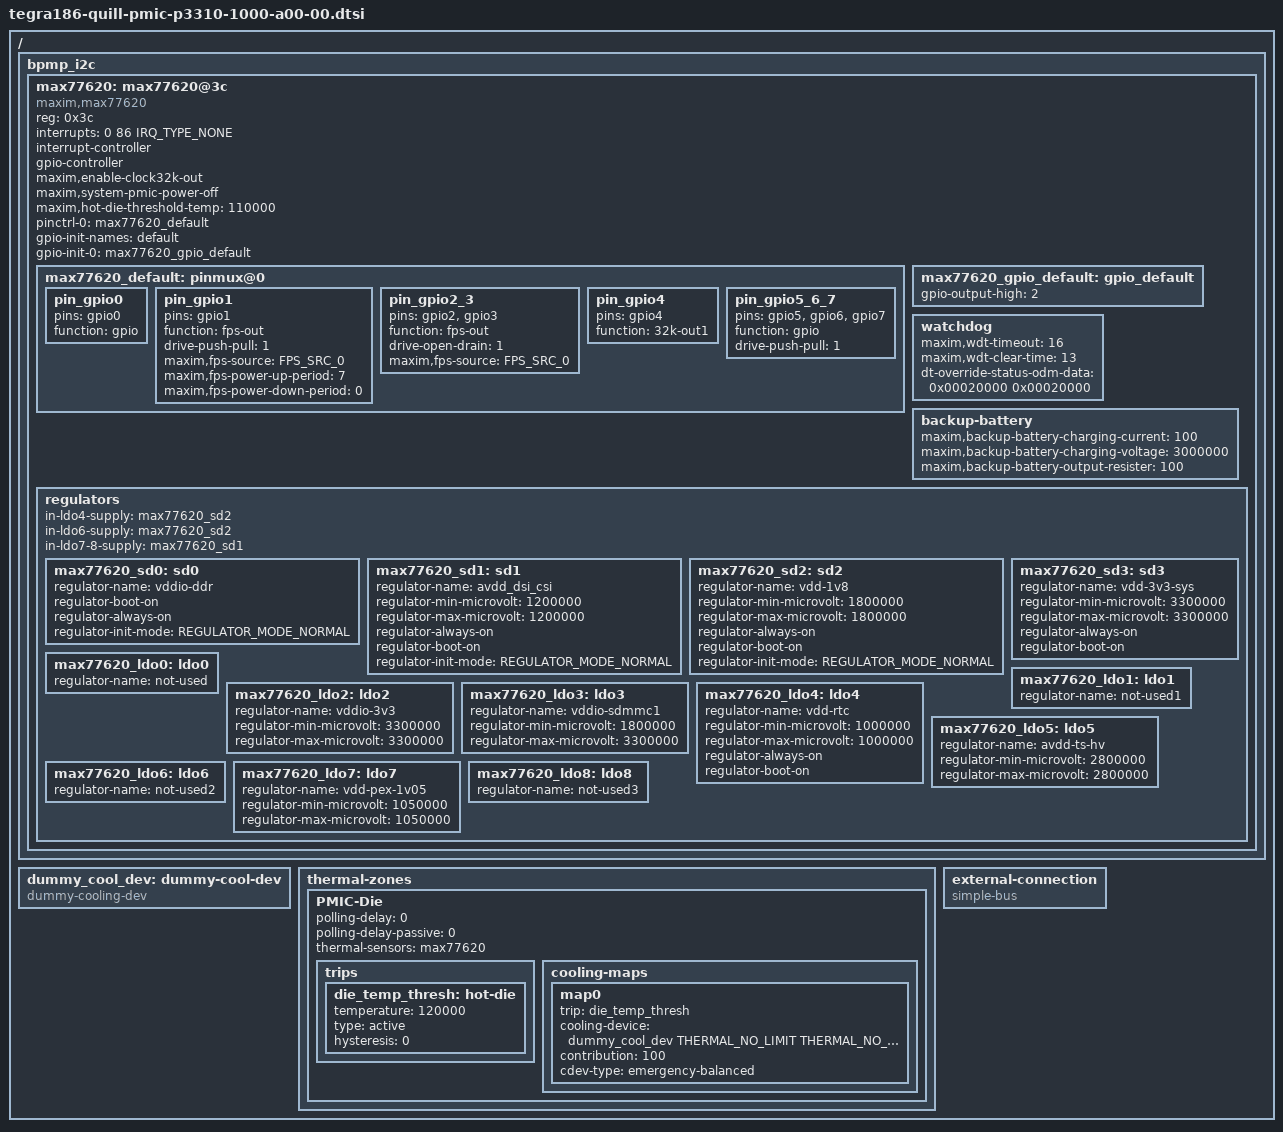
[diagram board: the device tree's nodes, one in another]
/*
 * Copyright (c) 2015, NVIDIA CORPORATION.  All rights reserved.
 *
 * This program is free software; you can redistribute it and/or modify
 * it under the terms of the GNU General Public License as published by
 * the Free Software Foundation; either version 2 of the License, or
 * (at your option) any later version.
 *
 * This program is distributed in the hope that it will be useful, but WITHOUT
 * ANY WARRANTY; without even the implied warranty of MERCHANTABILITY or
 * FITNESS FOR A PARTICULAR PURPOSE.  See the GNU General Public License for
 * more details.
 */

#include <dt-bindings/mfd/max77620.h>
#include <dt-bindings/regulator/regulator.h>
#include <dt-bindings/gpio/tegra-gpio.h>
#include <dt-bindings/thermal/thermal.h>
#include <dt-bindings/interrupt-controller/irq.h>

/ {
	bpmp_i2c {
		max77620: max77620@3c {
			compatible = "maxim,max77620";
			reg = <0x3c>;
			interrupts = <0 86 IRQ_TYPE_NONE>;

			#interrupt-cells = <2>;
                        interrupt-controller;

			gpio-controller;
			#gpio-cells = <2>;

			maxim,enable-clock32k-out;

			maxim,system-pmic-power-off;

			maxim,hot-die-threshold-temp = <110000>;
			#thermal-sensor-cells = <0>;

			pinctrl-names = "default";
			pinctrl-0 = <&max77620_default>;

			gpio-init-names = "default";
			gpio-init-0 = <&max77620_gpio_default>;

			max77620_default: pinmux@0 {
				pin_gpio0 {
					pins = "gpio0";
					function = "gpio";
				};

				pin_gpio1 {
					pins = "gpio1";
					function = "fps-out";
					drive-push-pull = <1>;
					maxim,fps-source = <FPS_SRC_0>;
					maxim,fps-power-up-period = <7>;
					maxim,fps-power-down-period = <0>;
				};

				pin_gpio2_3 {
					pins = "gpio2", "gpio3";
					function = "fps-out";
					drive-open-drain = <1>;
					maxim,fps-source = <FPS_SRC_0>;
				};

				pin_gpio4 {
					pins = "gpio4";
					function = "32k-out1";
				};

				pin_gpio5_6_7 {
					pins = "gpio5", "gpio6", "gpio7";
					function = "gpio";
					drive-push-pull = <1>;
				};
			};

			max77620_gpio_default:gpio_default {
				gpio-output-high = <2>;
			};

			watchdog {
				maxim,wdt-timeout = <16>;
				maxim,wdt-clear-time = <13>;
				status = "okay";
				dt-override-status-odm-data = <0x00020000 0x00020000>;
			};

			backup-battery {
				maxim,backup-battery-charging-current = <100>;
				maxim,backup-battery-charging-voltage = <3000000>;
				maxim,backup-battery-output-resister = <100>;
			};

			regulators {
				in-ldo4-supply = <&max77620_sd2>;
				in-ldo6-supply = <&max77620_sd2>;
				in-ldo7-8-supply = <&max77620_sd1>;

				max77620_sd0: sd0 {
					regulator-name = "vddio-ddr";
					regulator-boot-on;
					regulator-always-on;
					regulator-init-mode = <REGULATOR_MODE_NORMAL>;
				};

				max77620_sd1: sd1 {
					regulator-name = "avdd_dsi_csi";
					regulator-min-microvolt = <1200000>;
					regulator-max-microvolt = <1200000>;
					regulator-always-on;
					regulator-boot-on;
					regulator-init-mode = <REGULATOR_MODE_NORMAL>;
				};

				max77620_sd2: sd2 {
					regulator-name = "vdd-1v8";
					regulator-min-microvolt = <1800000>;
					regulator-max-microvolt = <1800000>;
					regulator-always-on;
					regulator-boot-on;
					regulator-init-mode = <REGULATOR_MODE_NORMAL>;
				};

				max77620_sd3: sd3 {
					regulator-name = "vdd-3v3-sys";
					regulator-min-microvolt = <3300000>;
					regulator-max-microvolt = <3300000>;
					regulator-always-on;
					regulator-boot-on;
				};

				max77620_ldo0: ldo0 {
					regulator-name = "not-used";
				};

				max77620_ldo1: ldo1 {
					regulator-name = "not-used1";
				};

				max77620_ldo2: ldo2 {
					regulator-name = "vddio-3v3";
					regulator-min-microvolt = <3300000>;
					regulator-max-microvolt = <3300000>;
				};

				max77620_ldo3: ldo3 {
					regulator-name = "vddio-sdmmc1";
					regulator-min-microvolt = <1800000>;
					regulator-max-microvolt = <3300000>;
				};

				max77620_ldo4: ldo4 {
					regulator-name = "vdd-rtc";
					regulator-min-microvolt = <1000000>;
					regulator-max-microvolt = <1000000>;
					regulator-always-on;
					regulator-boot-on;
				};

				max77620_ldo5: ldo5 {
					regulator-name = "avdd-ts-hv";
					regulator-min-microvolt = <2800000>;
					regulator-max-microvolt = <2800000>;
				};

				max77620_ldo6: ldo6 {
					regulator-name = "not-used2";
				};

				max77620_ldo7: ldo7 {
					regulator-name = "vdd-pex-1v05";
					regulator-min-microvolt = <1050000>;
					regulator-max-microvolt = <1050000>;
				};

				max77620_ldo8: ldo8 {
					regulator-name = "not-used3";
				};
			};
		};
	};

	dummy_cool_dev: dummy-cool-dev {
		compatible = "dummy-cooling-dev";
		#cooling-cells = <2>; /* min followed by max */
	};

	thermal-zones {
		PMIC-Die {
			polling-delay = <0>; /* milliseconds */
			polling-delay-passive = <0>; /* milliseconds */

			thermal-sensors = <&max77620>;
			trips {
				die_temp_thresh: hot-die {
					temperature = <120000>;
					type = "active";
					hysteresis = <0>;
				};
			};

			cooling-maps {
				map0 {
					trip = <&die_temp_thresh>;
					cooling-device = <&dummy_cool_dev THERMAL_NO_LIMIT
								THERMAL_NO_LIMIT>;
					contribution = <100>;
					cdev-type = "emergency-balanced";
				};
			};
		};
	};

	external-connection {
		compatible = "simple-bus";
		device_type = "external-connection";
		#address-cells = <1>;
		#size-cells = <0>;
	};
};
